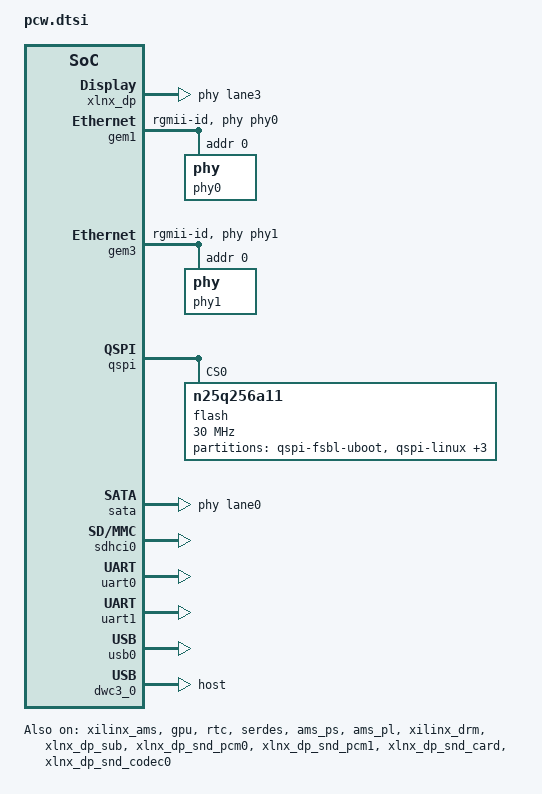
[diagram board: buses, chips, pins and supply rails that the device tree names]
/*
 * CAUTION: This file is automatically generated by Xilinx.
 * Version:  
 * Today is: Mon Mar  5 12:11:10 2018
 */


&lpd_dma_chan1 {
	status = "okay";
};
&lpd_dma_chan2 {
	status = "okay";
};
&lpd_dma_chan3 {
	status = "okay";
};
&lpd_dma_chan4 {
	status = "okay";
};
&lpd_dma_chan5 {
	status = "okay";
};
&lpd_dma_chan6 {
	status = "okay";
};
&lpd_dma_chan7 {
	status = "okay";
};
&lpd_dma_chan8 {
	status = "okay";
};
&xilinx_ams {
	status = "okay";
};
&xlnx_dp {
	phy-names = "dp-phy0","dp-phy1";
	phys = <&lane3 5 0 1 27000000>, 
		<&lane2 5 1 1 27000000>;
	status = "okay";
	xlnx,max-lanes = <2>;
};
&xlnx_dpdma {
	status = "okay";
};

&gem1 {
        phy-mode = "rgmii-id";
        status = "okay";
        xlnx,ptp-enet-clock = <0x0>;
	phy-handle = <&phy0>;
        phy0: phy@0 {
                reg = <0>;
        };

} ;

&gem3 {
        phy-mode = "rgmii-id";
        status = "okay";
        xlnx,ptp-enet-clock = <0x0>;
	phy-handle = <&phy1>;
        phy1: phy@0 {
                reg = <0>;
        };

} ;


&fpd_dma_chan1 {
	status = "okay";
};
&fpd_dma_chan2 {
	status = "okay";
};
&fpd_dma_chan3 {
	status = "okay";
};
&fpd_dma_chan4 {
	status = "okay";
};
&fpd_dma_chan5 {
	status = "okay";
};
&fpd_dma_chan6 {
	status = "okay";
};
&fpd_dma_chan7 {
	status = "okay";
};
&fpd_dma_chan8 {
	status = "okay";
};
&gpio {
	emio-gpio-width = <32>;
	gpio-mask-high = <0x0>;
	gpio-mask-low = <0x5600>;
	status = "okay";
};
&gpu {
	status = "okay";
};
&qspi {
	is-dual = <1>;
	num-cs = <1>;
	spi-rx-bus-width = <4>;
	spi-tx-bus-width = <4>;
	status = "okay";
	flash@0 {
		compatible = "n25q256a11";
		reg = <0x0>;
		spi-max-frequency = <30000000>;
		#address-cells = <1>;
		#size-cells = <1>;
		partition@qspi-fsbl-uboot {
			label = "qspi-fsbl-uboot";
			reg = <0x0 0x100000>;
		};
		partition@qspi-linux {
			label = "qspi-linux";
			reg = <0x100000 0x500000>;
		};
		partition@qspi-device-tree {
			label = "qspi-device-tree";
			reg = <0x600000 0x20000>;
		};
		partition@qspi-rootfs {
			label = "qspi-rootfs";
			reg = <0x620000 0x1400000>;
		};
		partition@qspi-bitstream {
			label = "qspi-bitstream";
			reg = <0x1a20000 0x400000>;
		};
	};
};
&pinctrl0 {
	status = "okay";
        pinctrl_usb0_default: usb0-default {
                mux {
                        groups = "usb0_0_grp";
                        function = "usb0";
                };

                conf {
                        groups = "usb0_0_grp";
                        slew-rate = <1>;
                        io-standard = <1>;
                };

                conf-rx {
                        pins = "MIO52", "MIO53", "MIO55";
                        bias-high-impedance;
                };

                conf-tx {
                        pins = "MIO54", "MIO56", "MIO57", "MIO58", "MIO59",
                               "MIO60", "MIO61", "MIO62", "MIO63";
                        bias-disable;
                };
        };

     	pinctrl_sdhci0_default: sdhci0-default {
        };
};
&rtc {
	status = "okay";
};
&fclk0 {
	status = "okay";
};
&sata {

	ceva,p0-cominit-params = <0x18401828>;
	ceva,p0-comwake-params = <0x614080e>;
	ceva,p0-burst-params = <0x13084a06>;
	ceva,p0-retry-params = <0x96a43ffc>;
	ceva,p1-cominit-params = <0x18401828>;
	ceva,p1-comwake-params = <0x614080e>;
	ceva,p1-burst-params = <0x13084a06>;
	ceva,p1-retry-params = <0x96a43ffc>;
	
	phy-names = "sata-phy";
	phys = <&lane0 0x1 0x0 0x0 125000000>,
		<&lane1 0x1 0x1 0x0 125000000>;
	status = "okay";
};
&sdhci0 {
	clock-frequency = <200000000>;
	status = "okay";
	xlnx,mio_bank = <0x0>;
	wp-inverted;
	/*pinctrl-names = "default";
	pinctrl-0 = <&pinctrl_sdhci0_default>;*/
	no-1-8-v;
};
&serdes {
	status = "okay";
};
&uart0 {
	device_type = "serial";
	port-number = <0>;
	status = "okay";
	u-boot,dm-pre-reloc ;
};
&uart1 {
	device_type = "serial";
	port-number = <1>;
	status = "okay";
	u-boot,dm-pre-reloc;
};
&usb0 {
	status = "okay";
	clock-names = "bus_clk";
	clocks = <0x3 0x20>;
	xlnx,usb-reset = <0x2faf080>;
};
&dwc3_0 {
	status = "okay";
	dr_mode = "host";
	maximum-speed = "high-speed";

} ;
/*&dwc3_0 {
	status = "okay";
	dr_mode = "host";
	phy-names = "usb3-phy";
	snps,usb3_lpm_capable;
	phys = <&lane0 4 0 0 100000000>;
};*/
&pss_ref_clk {
	clock-frequency = <50000000>;
};
&ams_ps {
	status = "okay";
};
&ams_pl {
	status = "okay";
};
&xilinx_drm {
	status = "okay";
};
&xlnx_dp_sub {
	status = "okay";
};
&xlnx_dp_snd_pcm0 {
	status = "okay";
};
&xlnx_dp_snd_pcm1 {
	status = "okay";
};
&xlnx_dp_snd_card {
	status = "okay";
};
&xlnx_dp_snd_codec0 {
	status = "okay";
};
